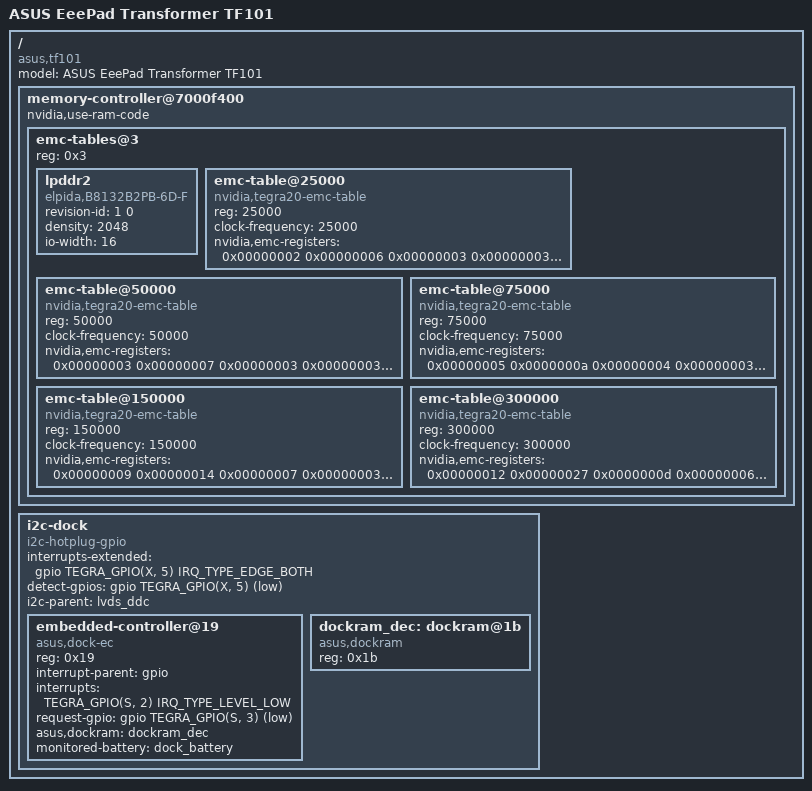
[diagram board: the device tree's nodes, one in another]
// SPDX-License-Identifier: GPL-2.0
/dts-v1/;

#include "tegra20-asus-transformer-common.dtsi"

/ {
	model = "ASUS EeePad Transformer TF101";
	compatible = "asus,tf101", "nvidia,tegra20";

	memory-controller@7000f400 {
		nvidia,use-ram-code;

		emc-tables@3 {
			reg = <0x3>;

			#address-cells = <1>;
			#size-cells = <0>;

			lpddr2 {
				compatible = "elpida,B8132B2PB-6D-F", "jedec,lpddr2-s4";
				revision-id = <1 0>;
				density = <2048>;
				io-width = <16>;
			};

			emc-table@25000 {
				reg = <25000>;
				compatible = "nvidia,tegra20-emc-table";
				clock-frequency = <25000>;
				nvidia,emc-registers = <0x00000002 0x00000006
					0x00000003 0x00000003 0x00000006 0x00000004
					0x00000002 0x00000009 0x00000003 0x00000003
					0x00000002 0x00000002 0x00000002 0x00000004
					0x00000003 0x00000008 0x0000000b 0x0000004d
					0x00000000 0x00000003 0x00000003 0x00000003
					0x00000008 0x00000001 0x0000000a 0x00000004
					0x00000003 0x00000008 0x00000004 0x00000006
					0x00000002 0x00000068 0x00000000 0x00000003
					0x00000000 0x00000000 0x00000282 0xa0ae04ae
					0x00070000 0x00000000 0x00000000 0x00000003
					0x00000000 0x00000000 0x00000000 0x00000000>;
			};

			emc-table@50000 {
				reg = <50000>;
				compatible = "nvidia,tegra20-emc-table";
				clock-frequency = <50000>;
				nvidia,emc-registers = <0x00000003 0x00000007
					0x00000003 0x00000003 0x00000006 0x00000004
					0x00000002 0x00000009 0x00000003 0x00000003
					0x00000002 0x00000002 0x00000002 0x00000005
					0x00000003 0x00000008 0x0000000b 0x0000009f
					0x00000000 0x00000003 0x00000003 0x00000003
					0x00000008 0x00000001 0x0000000a 0x00000007
					0x00000003 0x00000008 0x00000004 0x00000006
					0x00000002 0x000000d0 0x00000000 0x00000000
					0x00000000 0x00000000 0x00000282 0xa0ae04ae
					0x00070000 0x00000000 0x00000000 0x00000005
					0x00000000 0x00000000 0x00000000 0x00000000>;
			};

			emc-table@75000 {
				reg = <75000>;
				compatible = "nvidia,tegra20-emc-table";
				clock-frequency = <75000>;
				nvidia,emc-registers = <0x00000005 0x0000000a
					0x00000004 0x00000003 0x00000006 0x00000004
					0x00000002 0x00000009 0x00000003 0x00000003
					0x00000002 0x00000002 0x00000002 0x00000005
					0x00000003 0x00000008 0x0000000b 0x000000ff
					0x00000000 0x00000003 0x00000003 0x00000003
					0x00000008 0x00000001 0x0000000a 0x0000000b
					0x00000003 0x00000008 0x00000004 0x00000006
					0x00000002 0x00000138 0x00000000 0x00000000
					0x00000000 0x00000000 0x00000282 0xa0ae04ae
					0x00070000 0x00000000 0x00000000 0x00000007
					0x00000000 0x00000000 0x00000000 0x00000000>;
			};

			emc-table@150000 {
				reg = <150000>;
				compatible = "nvidia,tegra20-emc-table";
				clock-frequency = <150000>;
				nvidia,emc-registers = <0x00000009 0x00000014
					0x00000007 0x00000003 0x00000006 0x00000004
					0x00000002 0x00000009 0x00000003 0x00000003
					0x00000002 0x00000002 0x00000002 0x00000005
					0x00000003 0x00000008 0x0000000b 0x0000021f
					0x00000000 0x00000003 0x00000003 0x00000003
					0x00000008 0x00000001 0x0000000a 0x00000015
					0x00000003 0x00000008 0x00000004 0x00000006
					0x00000002 0x00000270 0x00000000 0x00000001
					0x00000000 0x00000000 0x00000282 0xa07c04ae
					0x007dc010 0x00000000 0x00000000 0x0000000e
					0x00000000 0x00000000 0x00000000 0x00000000>;
			};

			emc-table@300000 {
				reg = <300000>;
				compatible = "nvidia,tegra20-emc-table";
				clock-frequency = <300000>;
				nvidia,emc-registers = <0x00000012 0x00000027
					0x0000000d 0x00000006 0x00000007 0x00000005
					0x00000003 0x00000009 0x00000006 0x00000006
					0x00000003 0x00000003 0x00000002 0x00000006
					0x00000003 0x00000009 0x0000000c 0x0000045f
					0x00000000 0x00000004 0x00000004 0x00000006
					0x00000008 0x00000001 0x0000000e 0x0000002a
					0x00000003 0x0000000f 0x00000007 0x00000005
					0x00000002 0x000004e0 0x00000005 0x00000002
					0x00000000 0x00000000 0x00000282 0xe059048b
					0x007e0010 0x00000000 0x00000000 0x0000001b
					0x00000000 0x00000000 0x00000000 0x00000000>;
			};
		};
	};

	i2c-dock {
		compatible = "i2c-hotplug-gpio";

		#address-cells = <1>;
		#size-cells = <0>;

		interrupts-extended = <&gpio TEGRA_GPIO(X, 5) IRQ_TYPE_EDGE_BOTH>;
		detect-gpios = <&gpio TEGRA_GPIO(X, 5) GPIO_ACTIVE_LOW>;

		i2c-parent = <&lvds_ddc>;

		embedded-controller@19 {
			compatible = "asus,dock-ec", "asus,ec";
			reg = <0x19>;

			interrupt-parent = <&gpio>;
			interrupts = <TEGRA_GPIO(S, 2) IRQ_TYPE_LEVEL_LOW>;

			request-gpio = <&gpio TEGRA_GPIO(S, 3) GPIO_ACTIVE_LOW>;
			asus,dockram = <&dockram_dec>;

			monitored-battery = <&dock_battery>;
		};

		dockram_dec: dockram@1b {
			compatible = "asus,dockram";
			reg = <0x1b>;
		};
	};
};
